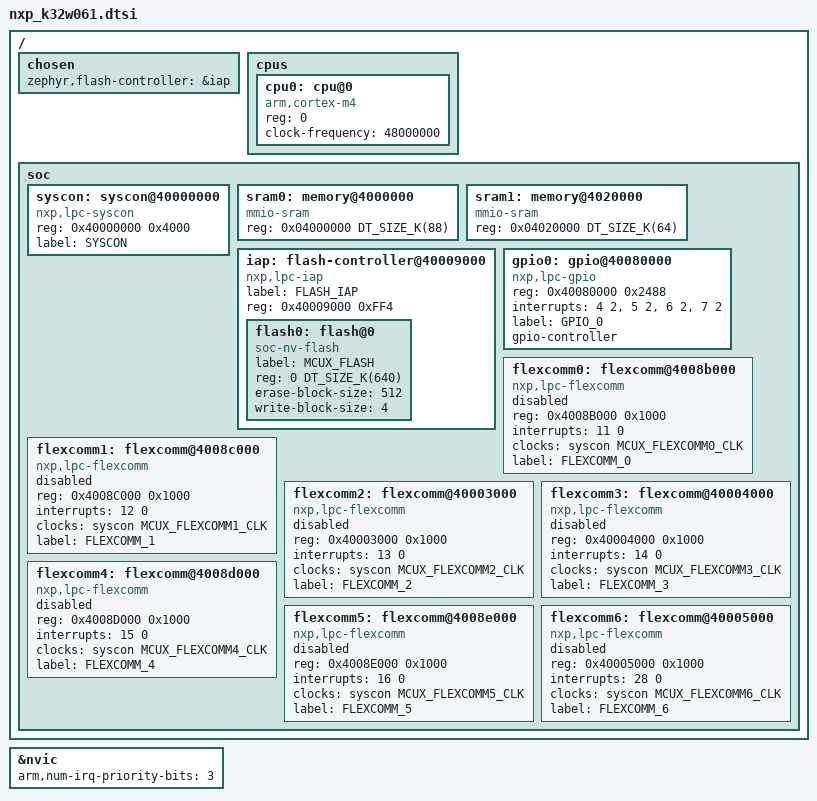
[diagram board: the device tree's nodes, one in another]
/*
 * Copyright 2021 Vincent van der Locht
 *
 * SPDX-License-Identifier: Apache-2.0
 */

#include <mem.h>
#include <arm/armv7-m.dtsi>
#include <dt-bindings/clock/mcux_lpc_syscon_clock.h>
#include <dt-bindings/gpio/gpio.h>
#include <dt-bindings/i2c/i2c.h>

/ {
	chosen {
		zephyr,flash-controller = &iap;
	};

	cpus {
		#address-cells = <1>;
		#size-cells = <0>;

		cpu0: cpu@0 {
			device_type = "cpu";
			compatible = "arm,cortex-m4";
			reg = <0>;
            clock-frequency = <48000000>;
		};
	};

	soc {

		syscon: syscon@40000000 {
			compatible = "nxp,lpc-syscon";
			reg = <0x40000000 0x4000>;
			label = "SYSCON";
			#clock-cells = <1>;
		};

        sram0: memory@4000000 {
            compatible = "mmio-sram";
            reg = <0x04000000 DT_SIZE_K(88)>;
        };

        sram1: memory@4020000 {
            compatible = "mmio-sram";
            reg = <0x04020000 DT_SIZE_K(64)>;
        };

		// mcg: clock-controller@40064000 {
		// 	compatible = "nxp,kw41z-mcg";
		// 	reg = <0x40064000 0x13>;
		// 	label = "MCG";
		// 	#clock-cells = <1>;
		// };

		// osc: clock-controller@40065000 {
		// 	compatible = "nxp,kw41z-osc";
		// 	reg = <0x40065000 0x4>;
		// 	enable-external-reference;
		// };

		// rtc: rtc@4000B000 {
		// 	compatible = "nxp,kinetis-rtc";
		// 	reg = <4000B000 0x10>;
		// 	interrupts = <29 0>;
		// 	clock-frequency = <32768>;
		// 	label = "RTC_0";
		// 	prescaler = <32768>;
		// };

		// sim: sim@40047000 {
		// 	compatible = "nxp,kinetis-sim";
		// 	reg = <0x40047000 0x1060>;
		// 	label = "SIM";

		// 	#clock-cells = <3>;
		// };

		iap: flash-controller@40009000 {
			compatible = "nxp,lpc-iap";
			label = "FLASH_IAP";
			reg = <0x40009000 0xFF4>;
			#address-cells = <1>;
			#size-cells = <1>;
			flash0: flash@0 {
				compatible = "soc-nv-flash";
				label = "MCUX_FLASH";
				reg = <0 DT_SIZE_K(640)>;
				erase-block-size = <512>;
				write-block-size = <4>;
			};
		};

		gpio0: gpio@40080000 {
			compatible = "nxp,lpc-gpio";
			reg = <0x40080000 0x2488>;
			interrupts = <4 2>,<5 2>,<6 2>,<7 2>;
			label = "GPIO_0";
			gpio-controller;
			#gpio-cells = <2>;
		};

		// spi0: spi@4002c000 {
		// 	compatible = "nxp,kinetis-dspi";
		// 	reg = <0x4002c000 0x9C>;
		// 	interrupts = <10 3>;
		// 	label = "SPI_0";
		// 	clocks = <&sim KINETIS_SIM_BUS_CLK 0x103C 12>;

		// 	#address-cells = <1>;
		// 	#size-cells = <0>;
		// };

		// spi1: spi@4002d000 {
		// 	compatible = "nxp,kinetis-dspi";
		// 	reg = <0x4002d000 0x9C>;
		// 	interrupts = <29 3>;
		// 	label = "SPI_1";
		// 	clocks = <&sim KINETIS_SIM_BUS_CLK 0x103C 13>;
		// 	status = "disabled";
		// 	#address-cells = <1>;
		// 	#size-cells = <0>;
		// };

		// tpm0: pwm@40038000 {
		// 	compatible = "nxp,kinetis-tpm";
		// 	reg = <0x40038000 0x88>;
		// 	interrupts = <0x84 0>;
		// 	/* channel information needed - fixme */
		// 	label = "PWM_0";
		// 	clocks = <&sim KINETIS_SIM_BUS_CLK 0x103C 24>;
		// 	status = "disabled";
		// 	#pwm-cells = <3>;
		// };

		// tpm1: pwm@40039000 {
		// 	compatible = "nxp,kinetis-tpm";
		// 	reg = <0x40039000 0x88>;
		// 	interrupts = <0x88 0>;
		// 	/* channel information needed - fixme */
		// 	label = "PWM_1";
		// 	clocks = <&sim KINETIS_SIM_BUS_CLK 0x103C 25>;
		// 	status = "disabled";
		// 	#pwm-cells = <3>;
		// };

		// tpm2: pwm@4003a000 {
		// 	compatible = "nxp,kinetis-tpm";
		// 	reg = <0x4003a000 0x88>;
		// 	interrupts = <0x8C 0>;
		// 	/* channel information needed - fixme */
		// 	label = "PWM_2";
		// 	clocks = <&sim KINETIS_SIM_BUS_CLK 0x103C 26>;
		// 	status = "disabled";
		// 	#pwm-cells = <3>;
		// };

		// adc0: adc@4003b000{
		// 	compatible = "nxp,kinetis-adc16";
		// 	reg = <0x4003b000 0x70>;
		// 	interrupts = <15 0>;
		// 	label = "ADC_0";
		// 	status = "disabled";
		// 	#io-channel-cells = <1>;
		// };

		// trng: random@40029000 {
		// 	compatible = "nxp,kinetis-trng";
		// 	reg = <0x40029000 0x1000>;
		// 	status = "okay";
		// 	interrupts = <13 0>;
		// 	label = "TRNG";
		// };

        // 27: Flexcomm Interface 0 (USART0, FLEXCOMM0)
		flexcomm0: flexcomm@4008b000 {
			compatible = "nxp,lpc-flexcomm";
			reg = <0x4008B000 0x1000>;
			interrupts = <11 0>;
			clocks = <&syscon MCUX_FLEXCOMM0_CLK>;
			label = "FLEXCOMM_0";
			status = "disabled";
		};

        // 28: Flexcomm Interface 1 (USART1, FLEXCOMM1)
		flexcomm1: flexcomm@4008c000 {
			compatible = "nxp,lpc-flexcomm";
			reg = <0x4008C000 0x1000>;
			interrupts = <12 0>;
			clocks = <&syscon MCUX_FLEXCOMM1_CLK>;
			label = "FLEXCOMM_1";
			status = "disabled";
		};

        // 29: Flexcomm Interface 2 (I2C0, FLEXCOMM2)
		flexcomm2: flexcomm@40003000 {
			compatible = "nxp,lpc-flexcomm";
			reg = <0x40003000 0x1000>;
			interrupts = <13 0>;
			clocks = <&syscon MCUX_FLEXCOMM2_CLK>;
			label = "FLEXCOMM_2";
			status = "disabled";
		};

        // 30: Flexcomm Interface 3 (I2C1, FLEXCOMM3)
		flexcomm3: flexcomm@40004000 {
			compatible = "nxp,lpc-flexcomm";
			reg = <0x40004000 0x1000>;
			interrupts = <14 0>;
			clocks = <&syscon MCUX_FLEXCOMM3_CLK>;
			label = "FLEXCOMM_3";
			status = "disabled";
		};

        // 31: Flexcomm Interface 4 (SPI0, FLEXCOMM4)
		flexcomm4: flexcomm@4008d000 {
			compatible = "nxp,lpc-flexcomm";
			reg = <0x4008D000 0x1000>;
			interrupts = <15 0>;
			clocks = <&syscon MCUX_FLEXCOMM4_CLK>;
			label = "FLEXCOMM_4";
			status = "disabled";
		};

        // 32: Flexcomm Interface 5 (SPI1, FLEXCOMM)
		flexcomm5: flexcomm@4008e000 {
			compatible = "nxp,lpc-flexcomm";
			reg = <0x4008E000 0x1000>;
			interrupts = <16 0>;
			clocks = <&syscon MCUX_FLEXCOMM5_CLK>;
			label = "FLEXCOMM_5";
			status = "disabled";
		};

        // 44: Flexcomm Interface6 (I2C2, FLEXCOMM6)
		flexcomm6: flexcomm@40005000 {
			compatible = "nxp,lpc-flexcomm";
			reg = <0x40005000 0x1000>;
			interrupts = <28 0>;
			clocks = <&syscon MCUX_FLEXCOMM6_CLK>;
			label = "FLEXCOMM_6";
			status = "disabled";
		};


	};
};

&nvic {
	arm,num-irq-priority-bits = <3>;
};
